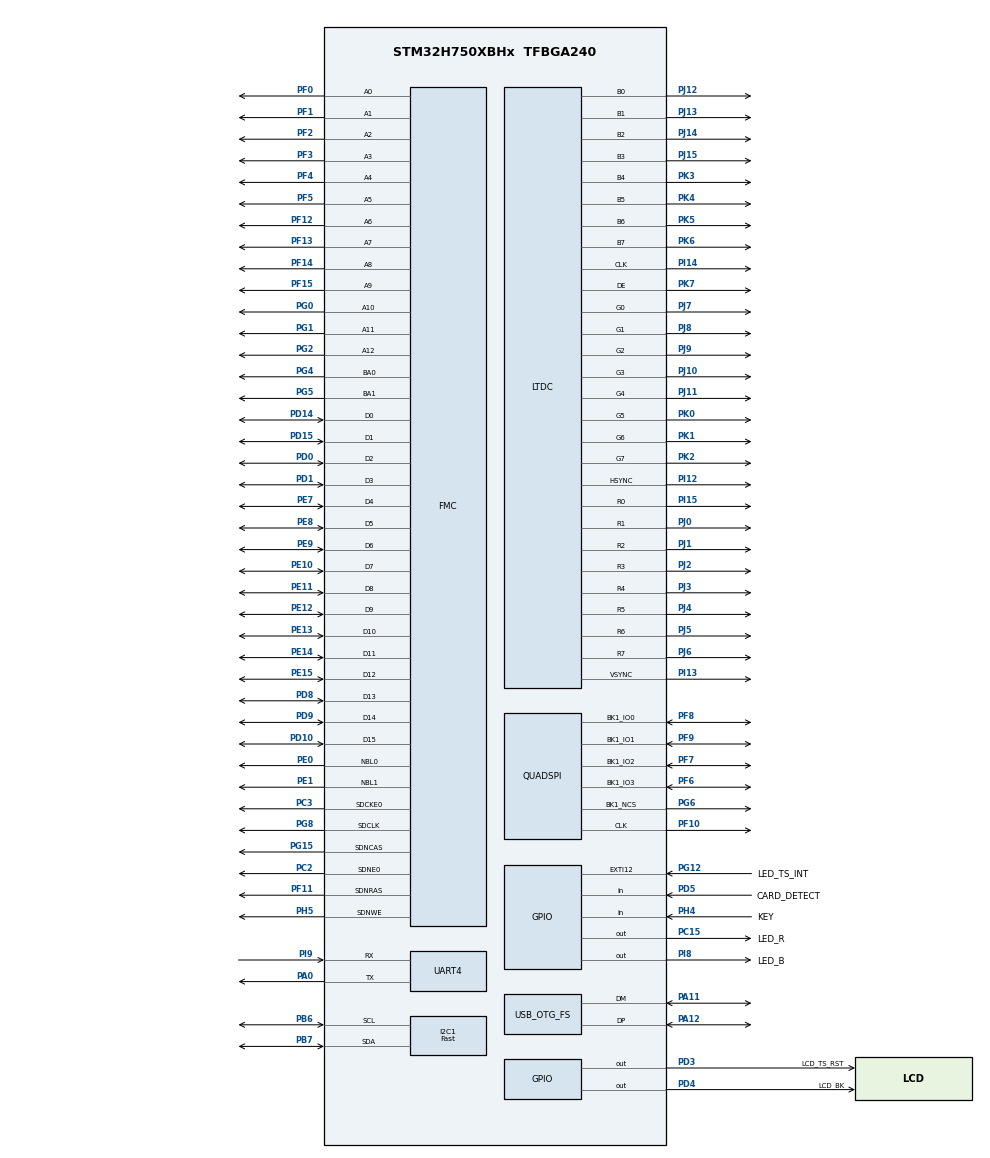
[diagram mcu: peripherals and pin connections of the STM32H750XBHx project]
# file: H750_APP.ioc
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CORTEX_M7.AccessPermission_S-Cortex_Memory_Protection_Unit_Region1_Settings_S=MPU_REGION_PRIV_RO
CORTEX_M7.AccessPermission_S-Cortex_Memory_Protection_Unit_Region2_Settings_S=MPU_REGION_FULL_ACCESS
CORTEX_M7.AccessPermission_S-Cortex_Memory_Protection_Unit_Region3_Settings_S=MPU_REGION_PRIV_RO
CORTEX_M7.AccessPermission_S-Cortex_Memory_Protection_Unit_Region4_Settings_S=MPU_REGION_FULL_ACCESS
CORTEX_M7.BaseAddress_S-Cortex_Memory_Protection_Unit_Region1_Settings_S=0x08000000
CORTEX_M7.BaseAddress_S-Cortex_Memory_Protection_Unit_Region2_Settings_S=0x24040000
CORTEX_M7.BaseAddress_S-Cortex_Memory_Protection_Unit_Region3_Settings_S=0x90000000
CORTEX_M7.BaseAddress_S-Cortex_Memory_Protection_Unit_Region4_Settings_S=0xC0000000
CORTEX_M7.CPU_DCache=Enabled
CORTEX_M7.CPU_ICache=Enabled
CORTEX_M7.DisableExec_S-Cortex_Memory_Protection_Unit_Region4_Settings_S=MPU_INSTRUCTION_ACCESS_DISABLE
CORTEX_M7.Enable_S-Cortex_Memory_Protection_Unit_Region1_Settings_S=MPU_REGION_ENABLE
CORTEX_M7.Enable_S-Cortex_Memory_Protection_Unit_Region2_Settings_S=MPU_REGION_ENABLE
CORTEX_M7.Enable_S-Cortex_Memory_Protection_Unit_Region3_Settings_S=MPU_REGION_ENABLE
CORTEX_M7.Enable_S-Cortex_Memory_Protection_Unit_Region4_Settings_S=MPU_REGION_ENABLE
CORTEX_M7.Enable_S-Cortex_Memory_Protection_Unit_Region5_Settings_S=__NULL
CORTEX_M7.IsBufferable_S-Cortex_Memory_Protection_Unit_Region4_Settings_S=MPU_ACCESS_BUFFERABLE
CORTEX_M7.IsCacheable_S-Cortex_Memory_Protection_Unit_Region1_Settings_S=MPU_ACCESS_CACHEABLE
CORTEX_M7.IsCacheable_S-Cortex_Memory_Protection_Unit_Region3_Settings_S=MPU_ACCESS_CACHEABLE
CORTEX_M7.IsCacheable_S-Cortex_Memory_Protection_Unit_Region4_Settings_S=MPU_ACCESS_CACHEABLE
CORTEX_M7.IsShareable_S-Cortex_Memory_Protection_Unit_Region2_Settings_S=MPU_ACCESS_SHAREABLE
CORTEX_M7.Number_S-Cortex_Memory_Protection_Unit_Region2_Settings_S=MPU_REGION_NUMBER2
CORTEX_M7.Number_S-Cortex_Memory_Protection_Unit_Region3_Settings_S=MPU_REGION_NUMBER3
CORTEX_M7.Number_S-Cortex_Memory_Protection_Unit_Region4_Settings_S=MPU_REGION_NUMBER4
CORTEX_M7.Size_S-Cortex_Memory_Protection_Unit_Region1_Settings_S=MPU_REGION_SIZE_128KB
CORTEX_M7.Size_S-Cortex_Memory_Protection_Unit_Region2_Settings_S=MPU_REGION_SIZE_512KB
CORTEX_M7.Size_S-Cortex_Memory_Protection_Unit_Region3_Settings_S=MPU_REGION_SIZE_16MB
CORTEX_M7.Size_S-Cortex_Memory_Protection_Unit_Region4_Settings_S=MPU_REGION_SIZE_32MB
CORTEX_M7.SubRegionDisable_S-Cortex_Memory_Protection_Unit_Region2_Settings_S=0xE0
CORTEX_M7.TypeExtField_S-Cortex_Memory_Protection_Unit_Region2_Settings_S=MPU_TEX_LEVEL1
CORTEX_M7.TypeExtField_S-Cortex_Memory_Protection_Unit_Region4_Settings_S=MPU_TEX_LEVEL1
CORTEX_M7.default_mode_Activation=1
Dma.I2C1_RX.0.Direction=DMA_PERIPH_TO_MEMORY
Dma.I2C1_RX.0.EventEnable=DISABLE
Dma.I2C1_RX.0.FIFOMode=DMA_FIFOMODE_DISABLE
Dma.I2C1_RX.0.Instance=DMA1_Stream0
Dma.I2C1_RX.0.MemDataAlignment=DMA_MDATAALIGN_BYTE
Dma.I2C1_RX.0.MemInc=DMA_MINC_ENABLE
Dma.I2C1_RX.0.Mode=DMA_NORMAL
Dma.I2C1_RX.0.PeriphDataAlignment=DMA_PDATAALIGN_BYTE
Dma.I2C1_RX.0.PeriphInc=DMA_PINC_DISABLE
Dma.I2C1_RX.0.Polarity=HAL_DMAMUX_REQ_GEN_RISING
Dma.I2C1_RX.0.Priority=DMA_PRIORITY_LOW
Dma.I2C1_RX.0.RequestNumber=1
Dma.I2C1_RX.0.SignalID=NONE
Dma.I2C1_RX.0.SyncEnable=DISABLE
Dma.I2C1_RX.0.SyncPolarity=HAL_DMAMUX_SYNC_NO_EVENT
Dma.I2C1_RX.0.SyncRequestNumber=1
Dma.I2C1_RX.0.SyncSignalID=NONE
Dma.I2C1_TX.1.Direction=DMA_MEMORY_TO_PERIPH
Dma.I2C1_TX.1.EventEnable=DISABLE
Dma.I2C1_TX.1.FIFOMode=DMA_FIFOMODE_DISABLE
Dma.I2C1_TX.1.Instance=DMA1_Stream1
Dma.I2C1_TX.1.MemDataAlignment=DMA_MDATAALIGN_BYTE
Dma.I2C1_TX.1.MemInc=DMA_MINC_ENABLE
Dma.I2C1_TX.1.Mode=DMA_NORMAL
Dma.I2C1_TX.1.PeriphDataAlignment=DMA_PDATAALIGN_BYTE
Dma.I2C1_TX.1.PeriphInc=DMA_PINC_DISABLE
Dma.I2C1_TX.1.Polarity=HAL_DMAMUX_REQ_GEN_RISING
Dma.I2C1_TX.1.Priority=DMA_PRIORITY_LOW
Dma.I2C1_TX.1.RequestNumber=1
Dma.I2C1_TX.1.SignalID=NONE
Dma.I2C1_TX.1.SyncEnable=DISABLE
Dma.I2C1_TX.1.SyncPolarity=HAL_DMAMUX_SYNC_NO_EVENT
Dma.I2C1_TX.1.SyncRequestNumber=1
Dma.I2C1_TX.1.SyncSignalID=NONE
Dma.Request0=I2C1_RX
Dma.Request1=I2C1_TX
FMC.CASLatency1=FMC_SDRAM_CAS_LATENCY_2
FMC.ColumnBitsNumber1=FMC_SDRAM_COLUMN_BITS_NUM_9
FMC.ExitSelfRefreshDelay1=8
FMC.LoadToActiveDelay1=2
FMC.RCDDelay1=2
FMC.RPDelay1=2
FMC.ReadBurst1=FMC_SDRAM_RBURST_ENABLE
FMC.RowCycleDelay1=6
FMC.SDClockPeriod1=FMC_SDRAM_CLOCK_PERIOD_2
FMC.SelfRefreshTime1=6
FMC.WriteRecoveryTime1=4
FREERTOS.Tasks01=defaultTask,24,256,StartDefaultTask,Default,NULL,Dynamic,NULL,NULL
FREERTOS.configENABLE_FPU=1
FREERTOS.configRECORD_STACK_HIGH_ADDRESS=1
FREERTOS.configTOTAL_HEAP_SIZE=65536
FREERTOS.configUSE_NEWLIB_REENTRANT=1
I2C1.CustomTiming=Disabled
I2C1.I2C_Fall_Time=0
I2C1.I2C_Rise_Time=0
I2C1.I2C_Speed_Mode=I2C_Fast
I2C1.Timing=0x00B03FDB
LTDC.ActiveH=272
LTDC.ActiveW=480
LTDC.Blue=255
LTDC.Green=0
LTDC.Green_L0=255
LTDC.HBP=40
LTDC.HFP=5
LTDC.HSync=1
LTDC.ImageHeight_L0=272
LTDC.ImageWidth_L0=480
LTDC.Layers=0
LTDC.Red=0
LTDC.VBP=8
LTDC.VFP=8
LTDC.VSync=1
LTDC.WindowX1_L0=480
LTDC.WindowY1_L0=272
Mcu.Family=STM32H7
Mcu.Name=STM32H750XBHx
Mcu.Package=TFBGA240
NVIC.DMA1_Stream0_IRQn=true\:5\:0\:false\:false\:true\:true\:false\:true\:true
NVIC.DMA1_Stream1_IRQn=true\:5\:0\:false\:false\:true\:true\:false\:true\:true
NVIC.EXTI15_10_IRQn=true\:5\:0\:false\:false\:true\:true\:true\:true\:true
NVIC.I2C1_ER_IRQn=true\:5\:0\:false\:false\:true\:true\:true\:true\:true
NVIC.I2C1_EV_IRQn=true\:5\:0\:false\:false\:true\:true\:true\:true\:true
NVIC.LTDC_IRQn=true\:5\:0\:false\:false\:true\:true\:true\:true\:true
NVIC.OTG_FS_EP1_IN_IRQn=true\:5\:0\:false\:false\:true\:true\:true\:true\:true
NVIC.OTG_FS_EP1_OUT_IRQn=true\:5\:0\:false\:false\:true\:true\:true\:true\:true
NVIC.OTG_FS_IRQn=true\:5\:0\:false\:false\:true\:true\:false\:true\:true
NVIC.PriorityGroup=NVIC_PRIORITYGROUP_4
PA0.Mode=Asynchronous
PA0.Signal=UART4_TX
PA11.Mode=Device_Only
PA11.Signal=USB_OTG_FS_DM
PA12.Mode=Device_Only
PA12.Signal=USB_OTG_FS_DP
PA13\ (JTMS/SWDIO).Mode=Serial_Wire
PA13\ (JTMS/SWDIO).Signal=DEBUG_JTMS-SWDIO
PA14\ (JTCK/SWCLK).Mode=Serial_Wire
PA14\ (JTCK/SWCLK).Signal=DEBUG_JTCK-SWCLK
PB6.GPIO_Pu=GPIO_PULLUP
PB6.Mode=I2C
PB6.Signal=I2C1_SCL
PB7.GPIO_Pu=GPIO_PULLUP
PB7.Mode=I2C
PB7.Signal=I2C1_SDA
PC14-OSC32_IN\ (OSC32_IN).Mode=LSE-External-Clock-Source
PC14-OSC32_IN\ (OSC32_IN).Signal=RCC_OSC32_IN
PC15-OSC32_OUT\ (OSC32_OUT).GPIO_Label=LED_R
PC15-OSC32_OUT\ (OSC32_OUT).PinState=GPIO_PIN_SET
PC15-OSC32_OUT\ (OSC32_OUT).Signal=GPIO_Output
PC2.Mode=SdramChipSelect1_1
PC2.Signal=FMC_SDNE0
PC3.Mode=SdramChipSelect1_1
PC3.Signal=FMC_SDCKE0
PD0.Signal=FMC_D2_DA2
PD1.Signal=FMC_D3_DA3
PD10.Signal=FMC_D15_DA15
PD14.Signal=FMC_D0_DA0
PD15.Signal=FMC_D1_DA1
PD3.GPIO_Label=LCD_TS_RST
PD3.Signal=GPIO_Output
PD4.GPIO_Label=LCD_BK
PD4.Signal=GPIO_Output
PD5.GPIO_Label=CARD_DETECT
PD5.Signal=GPIO_Input
PD8.Signal=FMC_D13_DA13
PD9.Signal=FMC_D14_DA14
PE0.Signal=FMC_NBL0
PE1.Signal=FMC_NBL1
PE10.Signal=FMC_D7_DA7
PE11.Signal=FMC_D8_DA8
PE12.Signal=FMC_D9_DA9
PE13.Signal=FMC_D10_DA10
PE14.Signal=FMC_D11_DA11
PE15.Signal=FMC_D12_DA12
PE7.Signal=FMC_D4_DA4
PE8.Signal=FMC_D5_DA5
PE9.Signal=FMC_D6_DA6
PF0.Signal=FMC_A0
PF1.Signal=FMC_A1
PF10.Mode=Single Bank 1
PF10.Signal=QUADSPI_CLK
PF11.Signal=FMC_SDNRAS
PF12.Signal=FMC_A6
PF13.Signal=FMC_A7
PF14.Signal=FMC_A8
PF15.Signal=FMC_A9
PF2.Signal=FMC_A2
PF3.Signal=FMC_A3
PF4.Signal=FMC_A4
PF5.Signal=FMC_A5
PF6.Mode=Single Bank 1
PF6.Signal=QUADSPI_BK1_IO3
PF7.Mode=Single Bank 1
PF7.Signal=QUADSPI_BK1_IO2
PF8.Mode=Single Bank 1
PF8.Signal=QUADSPI_BK1_IO0
PF9.Mode=Single Bank 1
PF9.Signal=QUADSPI_BK1_IO1
PG0.Signal=FMC_A10
PG1.Signal=FMC_A11
PG12.GPIO_Label=LED_TS_INT
PG12.GPIO_PuPd=GPIO_PULLDOWN
PG12.Signal=GPXTI12
PG15.Signal=FMC_SDNCAS
PG2.Signal=FMC_A12
PG4.Signal=FMC_A14_BA0
PG5.Signal=FMC_A15_BA1
PG6.Mode=Single Bank 1
PG6.Signal=QUADSPI_BK1_NCS
PG8.Signal=FMC_SDCLK
PH0-OSC_IN\ (PH0).Mode=HSE-External-Oscillator
PH0-OSC_IN\ (PH0).Signal=RCC_OSC_IN
PH1-OSC_OUT\ (PH1).Mode=HSE-External-Oscillator
PH1-OSC_OUT\ (PH1).Signal=RCC_OSC_OUT
PH4.GPIO_Label=KEY
PH4.Signal=GPIO_Input
PH5.Signal=FMC_SDNWE
PI12.GPIO_Speed=GPIO_SPEED_FREQ_HIGH
PI12.Mode=RGB888
PI12.Signal=LTDC_HSYNC
PI13.GPIO_Speed=GPIO_SPEED_FREQ_HIGH
PI13.Mode=RGB888
PI13.Signal=LTDC_VSYNC
PI14.GPIO_Speed=GPIO_SPEED_FREQ_HIGH
PI14.Mode=RGB888
PI14.Signal=LTDC_CLK
PI15.GPIO_Speed=GPIO_SPEED_FREQ_HIGH
PI15.Mode=RGB888
PI15.Signal=LTDC_R0
PI8.GPIO_Label=LED_B
PI8.PinState=GPIO_PIN_SET
PI8.Signal=GPIO_Output
PI9.Mode=Asynchronous
PI9.Signal=UART4_RX
PJ0.GPIO_Speed=GPIO_SPEED_FREQ_HIGH
PJ0.Mode=RGB888
PJ0.Signal=LTDC_R1
PJ1.GPIO_Speed=GPIO_SPEED_FREQ_HIGH
PJ1.Mode=RGB888
PJ1.Signal=LTDC_R2
PJ10.GPIO_Speed=GPIO_SPEED_FREQ_HIGH
PJ10.Mode=RGB888
PJ10.Signal=LTDC_G3
PJ11.GPIO_Speed=GPIO_SPEED_FREQ_HIGH
PJ11.Mode=RGB888
PJ11.Signal=LTDC_G4
PJ12.GPIO_Speed=GPIO_SPEED_FREQ_HIGH
PJ12.Mode=RGB888
PJ12.Signal=LTDC_B0
PJ13.GPIO_Speed=GPIO_SPEED_FREQ_HIGH
PJ13.Mode=RGB888
PJ13.Signal=LTDC_B1
PJ14.GPIO_Speed=GPIO_SPEED_FREQ_HIGH
PJ14.Mode=RGB888
PJ14.Signal=LTDC_B2
PJ15.GPIO_Speed=GPIO_SPEED_FREQ_HIGH
PJ15.Mode=RGB888
PJ15.Signal=LTDC_B3
PJ2.GPIO_Speed=GPIO_SPEED_FREQ_HIGH
PJ2.Mode=RGB888
PJ2.Signal=LTDC_R3
PJ3.GPIO_Speed=GPIO_SPEED_FREQ_HIGH
PJ3.Mode=RGB888
PJ3.Signal=LTDC_R4
PJ4.GPIO_Speed=GPIO_SPEED_FREQ_HIGH
PJ4.Mode=RGB888
PJ4.Signal=LTDC_R5
PJ5.GPIO_Speed=GPIO_SPEED_FREQ_HIGH
PJ5.Mode=RGB888
PJ5.Signal=LTDC_R6
PJ6.GPIO_Speed=GPIO_SPEED_FREQ_HIGH
PJ6.Mode=RGB888
PJ6.Signal=LTDC_R7
PJ7.GPIO_Speed=GPIO_SPEED_FREQ_HIGH
PJ7.Mode=RGB888
PJ7.Signal=LTDC_G0
PJ8.GPIO_Speed=GPIO_SPEED_FREQ_HIGH
PJ8.Mode=RGB888
PJ8.Signal=LTDC_G1
PJ9.GPIO_Speed=GPIO_SPEED_FREQ_HIGH
PJ9.Mode=RGB888
PJ9.Signal=LTDC_G2
PK0.GPIO_Speed=GPIO_SPEED_FREQ_HIGH
PK0.Mode=RGB888
PK0.Signal=LTDC_G5
PK1.GPIO_Speed=GPIO_SPEED_FREQ_HIGH
PK1.Mode=RGB888
PK1.Signal=LTDC_G6
PK2.GPIO_Speed=GPIO_SPEED_FREQ_HIGH
PK2.Mode=RGB888
PK2.Signal=LTDC_G7
PK3.GPIO_Speed=GPIO_SPEED_FREQ_HIGH
PK3.Mode=RGB888
PK3.Signal=LTDC_B4
PK4.GPIO_Speed=GPIO_SPEED_FREQ_HIGH
PK4.Mode=RGB888
PK4.Signal=LTDC_B5
PK5.GPIO_Speed=GPIO_SPEED_FREQ_HIGH
PK5.Mode=RGB888
PK5.Signal=LTDC_B6
PK6.GPIO_Speed=GPIO_SPEED_FREQ_HIGH
PK6.Mode=RGB888
PK6.Signal=LTDC_B7
PK7.GPIO_Speed=GPIO_SPEED_FREQ_HIGH
PK7.Mode=RGB888
PK7.Signal=LTDC_DE
ProjectManager.HeapSize=0x400
ProjectManager.StackSize=0x800
ProjectManager.TargetToolchain=CMake
QUADSPI.ClockPrescaler=1
QUADSPI.FlashSize=24
RCC.ADCCLockSelection=RCC_ADCCLKSOURCE_CLKP
RCC.ADCFreq_Value=64000000
RCC.APB1Freq_Value=120000000
RCC.APB2Freq_Value=120000000
RCC.APB3Freq_Value=120000000
RCC.APB4Freq_Value=120000000
RCC.CortexFreq_Value=480000000
RCC.D1PPRE=RCC_APB3_DIV2
RCC.D2PPRE1=RCC_APB1_DIV2
RCC.D2PPRE2=RCC_APB2_DIV2
RCC.D3PPRE=RCC_APB4_DIV2
RCC.DIVM1=5
RCC.DIVM2=2
RCC.DIVM3=1
RCC.DIVN1=192
RCC.DIVN2=48
RCC.DIVN3=6
RCC.DIVQ2=3
RCC.DIVQ3=1
RCC.DIVR2=3
RCC.DIVR3=15
RCC.FMCCLockSelection=RCC_FMCCLKSOURCE_PLL2
RCC.HCLKFreq_Value=240000000
RCC.HPRE=RCC_HCLK_DIV2
RCC.PLL2FRACN=0
RCC.PLL3FRACN=0
RCC.PLLFRACN=0
RCC.PLLSourceVirtual=RCC_PLLSOURCE_HSE
RCC.QSPICLockSelection=RCC_QSPICLKSOURCE_PLL2
RCC.SDMMC1CLockSelection=RCC_SDMMCCLKSOURCE_PLL2
RCC.SYSCLKFreq_VALUE=480000000
RCC.SYSCLKSource=RCC_SYSCLKSOURCE_PLLCLK
RCC.USBCLockSelection=RCC_USBCLKSOURCE_HSI48
RCC.USBFreq_Value=48000000
SH.FMC_A0.0=FMC_A0,13b-sda1
SH.FMC_A1.0=FMC_A1,13b-sda1
SH.FMC_A10.0=FMC_A10,13b-sda1
SH.FMC_A11.0=FMC_A11,13b-sda1
SH.FMC_A12.0=FMC_A12,13b-sda1
SH.FMC_A14_BA0.0=FMC_BA0,FourSdramBanks1
SH.FMC_A15_BA1.0=FMC_BA1,FourSdramBanks1
SH.FMC_A2.0=FMC_A2,13b-sda1
SH.FMC_A3.0=FMC_A3,13b-sda1
SH.FMC_A4.0=FMC_A4,13b-sda1
SH.FMC_A5.0=FMC_A5,13b-sda1
SH.FMC_A6.0=FMC_A6,13b-sda1
SH.FMC_A7.0=FMC_A7,13b-sda1
SH.FMC_A8.0=FMC_A8,13b-sda1
SH.FMC_A9.0=FMC_A9,13b-sda1
SH.FMC_D0_DA0.0=FMC_D0,sd-16b-d1
SH.FMC_D10_DA10.0=FMC_D10,sd-16b-d1
SH.FMC_D11_DA11.0=FMC_D11,sd-16b-d1
SH.FMC_D12_DA12.0=FMC_D12,sd-16b-d1
SH.FMC_D13_DA13.0=FMC_D13,sd-16b-d1
SH.FMC_D14_DA14.0=FMC_D14,sd-16b-d1
SH.FMC_D15_DA15.0=FMC_D15,sd-16b-d1
SH.FMC_D1_DA1.0=FMC_D1,sd-16b-d1
SH.FMC_D2_DA2.0=FMC_D2,sd-16b-d1
SH.FMC_D3_DA3.0=FMC_D3,sd-16b-d1
SH.FMC_D4_DA4.0=FMC_D4,sd-16b-d1
SH.FMC_D5_DA5.0=FMC_D5,sd-16b-d1
SH.FMC_D6_DA6.0=FMC_D6,sd-16b-d1
SH.FMC_D7_DA7.0=FMC_D7,sd-16b-d1
SH.FMC_D8_DA8.0=FMC_D8,sd-16b-d1
SH.FMC_D9_DA9.0=FMC_D9,sd-16b-d1
SH.FMC_NBL0.0=FMC_NBL0,Sd2ByteEnable1
SH.FMC_NBL1.0=FMC_NBL1,Sd2ByteEnable1
SH.FMC_SDCLK.0=FMC_SDCLK,13b-sda1
SH.FMC_SDNCAS.0=FMC_SDNCAS,13b-sda1
SH.FMC_SDNRAS.0=FMC_SDNRAS,13b-sda1
SH.FMC_SDNWE.0=FMC_SDNWE,13b-sda1
USB_DEVICE.CLASS_NAME_FS=HID
USB_DEVICE.USBD_MAX_NUM_CONFIGURATION-HID_FS=1
USB_DEVICE.USBD_SELF_POWERED-HID_FS=0
USB_DEVICE.VirtualMode-HID_FS=Hid
USB_DEVICE.VirtualModeFS=Hid_FS
USB_OTG_FS.VirtualMode=Device_Only
VP_FREERTOS_VS_CMSIS_V2.Mode=CMSIS_V2
VP_MEMORYMAP_VS_MEMORYMAP.Mode=CurAppReg
VP_USB_DEVICE_VS_USB_DEVICE_HID_FS.Mode=HID_FS
board=custom

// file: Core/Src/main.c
/* USER CODE BEGIN Header */
/**
 ******************************************************************************
 * @file           : main.c
 * @brief          : Main program body
 ******************************************************************************
 * @attention
 *
 * Copyright (c) 2025 STMicroelectronics.
 * All rights reserved.
 *
 * This software is licensed under terms that can be found in the LICENSE file
 * in the root directory of this software component.
 * If no LICENSE file comes with this software, it is provided AS-IS.
 *
 ******************************************************************************
 */
/* USER CODE END Header */
#include "main.h"
#include "cmsis_os.h"
#include "dma.h"
#include "i2c.h"
#include "ltdc.h"
#include "memorymap.h"
#include "usart.h"
#include "usb_device.h"
#include "gpio.h"

/* USER CODE BEGIN Includes */
#include "SEGGER_RTT.h"
#include "usbd_hid.h"

/* USER CODE END Includes */

void SystemClock_Config(void);
void PeriphCommonClock_Config(void);
static void MPU_Config(void);
void MX_FREERTOS_Init(void);

int main(void)
{

  /* MPU Configuration--------------------------------------------------------*/
  MPU_Config();

  /* Enable the CPU Cache */

  /* Enable I-Cache---------------------------------------------------------*/
  SCB_EnableICache();

  /* Enable D-Cache---------------------------------------------------------*/
  SCB_EnableDCache();

  /* MCU Configuration--------------------------------------------------------*/

  /* Reset of all peripherals, Initializes the Flash interface and the Systick. */
  HAL_Init();

  /* USER CODE BEGIN Init */
#if 0
  /* USER CODE END Init */

  /* Configure the system clock */
  SystemClock_Config();

  /* Configure the peripherals common clocks */
  PeriphCommonClock_Config();

  /* USER CODE BEGIN SysInit */
#endif
  /* USER CODE END SysInit */

  /* Initialize all configured peripherals */
  MX_GPIO_Init();
  MX_DMA_Init();
  MX_LTDC_Init();
  MX_I2C1_Init();
  MX_UART4_Init();
  /* USER CODE BEGIN 2 */
  SEGGER_RTT_Init();
  /* USER CODE END 2 */

  /* Init scheduler */
  osKernelInitialize();

  /* Call init function for freertos objects (in cmsis_os2.c) */
  MX_FREERTOS_Init();

  /* Start scheduler */
  osKernelStart();

  /* We should never get here as control is now taken by the scheduler */

  /* Infinite loop */
    while (1)
    {

    }
}

void SystemClock_Config(void)
{
  RCC_OscInitTypeDef RCC_OscInitStruct = {0};
  RCC_ClkInitTypeDef RCC_ClkInitStruct = {0};

  /** Supply configuration update enable
  */
  HAL_PWREx_ConfigSupply(PWR_LDO_SUPPLY);

  /** Configure the main internal regulator output voltage
  */
  __HAL_PWR_VOLTAGESCALING_CONFIG(PWR_REGULATOR_VOLTAGE_SCALE1);

  while(!__HAL_PWR_GET_FLAG(PWR_FLAG_VOSRDY)) {}

  __HAL_RCC_SYSCFG_CLK_ENABLE();
  __HAL_PWR_VOLTAGESCALING_CONFIG(PWR_REGULATOR_VOLTAGE_SCALE0);

  while(!__HAL_PWR_GET_FLAG(PWR_FLAG_VOSRDY)) {}

  /** Initializes the RCC Oscillators according to the specified parameters
  * in the RCC_OscInitTypeDef structure.
  */
  RCC_OscInitStruct.OscillatorType = RCC_OSCILLATORTYPE_HSI48|RCC_OSCILLATORTYPE_HSE;
  RCC_OscInitStruct.HSEState = RCC_HSE_ON;
  RCC_OscInitStruct.HSI48State = RCC_HSI48_ON;
  RCC_OscInitStruct.PLL.PLLState = RCC_PLL_ON;
  RCC_OscInitStruct.PLL.PLLSource = RCC_PLLSOURCE_HSE;
  RCC_OscInitStruct.PLL.PLLM = 5;
  RCC_OscInitStruct.PLL.PLLN = 192;
  RCC_OscInitStruct.PLL.PLLP = 2;
  RCC_OscInitStruct.PLL.PLLQ = 2;
  RCC_OscInitStruct.PLL.PLLR = 2;
  RCC_OscInitStruct.PLL.PLLRGE = RCC_PLL1VCIRANGE_2;
  RCC_OscInitStruct.PLL.PLLVCOSEL = RCC_PLL1VCOWIDE;
  RCC_OscInitStruct.PLL.PLLFRACN = 0;
  if (HAL_RCC_OscConfig(&RCC_OscInitStruct) != HAL_OK)
  {
    Error_Handler();
  }

  /** Initializes the CPU, AHB and APB buses clocks
  */
  RCC_ClkInitStruct.ClockType = RCC_CLOCKTYPE_HCLK|RCC_CLOCKTYPE_SYSCLK
                              |RCC_CLOCKTYPE_PCLK1|RCC_CLOCKTYPE_PCLK2
                              |RCC_CLOCKTYPE_D3PCLK1|RCC_CLOCKTYPE_D1PCLK1;
  RCC_ClkInitStruct.SYSCLKSource = RCC_SYSCLKSOURCE_PLLCLK;
  RCC_ClkInitStruct.SYSCLKDivider = RCC_SYSCLK_DIV1;
  RCC_ClkInitStruct.AHBCLKDivider = RCC_HCLK_DIV2;
  RCC_ClkInitStruct.APB3CLKDivider = RCC_APB3_DIV2;
  RCC_ClkInitStruct.APB1CLKDivider = RCC_APB1_DIV2;
  RCC_ClkInitStruct.APB2CLKDivider = RCC_APB2_DIV2;
  RCC_ClkInitStruct.APB4CLKDivider = RCC_APB4_DIV2;

  if (HAL_RCC_ClockConfig(&RCC_ClkInitStruct, FLASH_LATENCY_4) != HAL_OK)
  {
    Error_Handler();
  }
}

void PeriphCommonClock_Config(void)
{
  RCC_PeriphCLKInitTypeDef PeriphClkInitStruct = {0};

  /** Initializes the peripherals clock
  */
  PeriphClkInitStruct.PeriphClockSelection = RCC_PERIPHCLK_FMC|RCC_PERIPHCLK_QSPI;
  PeriphClkInitStruct.PLL2.PLL2M = 2;
  PeriphClkInitStruct.PLL2.PLL2N = 48;
  PeriphClkInitStruct.PLL2.PLL2P = 2;
  PeriphClkInitStruct.PLL2.PLL2Q = 3;
  PeriphClkInitStruct.PLL2.PLL2R = 3;
  PeriphClkInitStruct.PLL2.PLL2RGE = RCC_PLL2VCIRANGE_3;
  PeriphClkInitStruct.PLL2.PLL2VCOSEL = RCC_PLL2VCOWIDE;
  PeriphClkInitStruct.PLL2.PLL2FRACN = 0;
  PeriphClkInitStruct.FmcClockSelection = RCC_FMCCLKSOURCE_PLL2;
  PeriphClkInitStruct.QspiClockSelection = RCC_QSPICLKSOURCE_PLL2;
  if (HAL_RCCEx_PeriphCLKConfig(&PeriphClkInitStruct) != HAL_OK)
  {
    Error_Handler();
  }
}

 /* MPU Configuration */

void MPU_Config(void)
{
  MPU_Region_InitTypeDef MPU_InitStruct = {0};

  /* Disables the MPU */
  HAL_MPU_Disable();

  /** Initializes and configures the Region and the memory to be protected
  */
  MPU_InitStruct.Enable = MPU_REGION_ENABLE;
  MPU_InitStruct.Number = MPU_REGION_NUMBER0;
  MPU_InitStruct.BaseAddress = 0x0;
  MPU_InitStruct.Size = MPU_REGION_SIZE_4GB;
  MPU_InitStruct.SubRegionDisable = 0x87;
  MPU_InitStruct.TypeExtField = MPU_TEX_LEVEL0;
  MPU_InitStruct.AccessPermission = MPU_REGION_NO_ACCESS;
  MPU_InitStruct.DisableExec = MPU_INSTRUCTION_ACCESS_DISABLE;
  MPU_InitStruct.IsShareable = MPU_ACCESS_SHAREABLE;
  MPU_InitStruct.IsCacheable = MPU_ACCESS_NOT_CACHEABLE;
  MPU_InitStruct.IsBufferable = MPU_ACCESS_NOT_BUFFERABLE;

  HAL_MPU_ConfigRegion(&MPU_InitStruct);

  /** Initializes and configures the Region and the memory to be protected
  */
  MPU_InitStruct.Number = MPU_REGION_NUMBER1;
  MPU_InitStruct.BaseAddress = 0x08000000;
  MPU_InitStruct.Size = MPU_REGION_SIZE_128KB;
  MPU_InitStruct.SubRegionDisable = 0x0;
  MPU_InitStruct.AccessPermission = MPU_REGION_PRIV_RO;
  MPU_InitStruct.DisableExec = MPU_INSTRUCTION_ACCESS_ENABLE;
  MPU_InitStruct.IsShareable = MPU_ACCESS_NOT_SHAREABLE;
  MPU_InitStruct.IsCacheable = MPU_ACCESS_CACHEABLE;

  HAL_MPU_ConfigRegion(&MPU_InitStruct);

  /** Initializes and configures the Region and the memory to be protected
  */
  MPU_InitStruct.Number = MPU_REGION_NUMBER2;
  MPU_InitStruct.BaseAddress = 0x24040000;
  MPU_InitStruct.Size = MPU_REGION_SIZE_512KB;
  MPU_InitStruct.SubRegionDisable = 0xE0;
  MPU_InitStruct.TypeExtField = MPU_TEX_LEVEL1;
  MPU_InitStruct.AccessPermission = MPU_REGION_FULL_ACCESS;
  MPU_InitStruct.IsShareable = MPU_ACCESS_SHAREABLE;
  MPU_InitStruct.IsCacheable = MPU_ACCESS_NOT_CACHEABLE;

  HAL_MPU_ConfigRegion(&MPU_InitStruct);

  /** Initializes and configures the Region and the memory to be protected
  */
  MPU_InitStruct.Number = MPU_REGION_NUMBER3;
  MPU_InitStruct.BaseAddress = 0x90000000;
  MPU_InitStruct.Size = MPU_REGION_SIZE_16MB;
  MPU_InitStruct.SubRegionDisable = 0x0;
  MPU_InitStruct.TypeExtField = MPU_TEX_LEVEL0;
  MPU_InitStruct.AccessPermission = MPU_REGION_PRIV_RO;
  MPU_InitStruct.IsShareable = MPU_ACCESS_NOT_SHAREABLE;
  MPU_InitStruct.IsCacheable = MPU_ACCESS_CACHEABLE;

  HAL_MPU_ConfigRegion(&MPU_InitStruct);

  /** Initializes and configures the Region and the memory to be protected
  */
  MPU_InitStruct.Number = MPU_REGION_NUMBER4;
  MPU_InitStruct.BaseAddress = 0xC0000000;
  MPU_InitStruct.Size = MPU_REGION_SIZE_32MB;
  MPU_InitStruct.TypeExtField = MPU_TEX_LEVEL1;
  MPU_InitStruct.AccessPermission = MPU_REGION_FULL_ACCESS;
  MPU_InitStruct.DisableExec = MPU_INSTRUCTION_ACCESS_DISABLE;
  MPU_InitStruct.IsBufferable = MPU_ACCESS_BUFFERABLE;

  HAL_MPU_ConfigRegion(&MPU_InitStruct);
  /* Enables the MPU */
  HAL_MPU_Enable(MPU_PRIVILEGED_DEFAULT);

}

void Error_Handler(void)
{
    __disable_irq();
    while (1)
    {
    }
}

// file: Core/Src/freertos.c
/* USER CODE BEGIN Header */
/**
  ******************************************************************************
  * File Name          : freertos.c
  * Description        : Code for freertos applications
  ******************************************************************************
  * @attention
  *
  * Copyright (c) 2025 STMicroelectronics.
  * All rights reserved.
  *
  * This software is licensed under terms that can be found in the LICENSE file
  * in the root directory of this software component.
  * If no LICENSE file comes with this software, it is provided AS-IS.
  *
  ******************************************************************************
  */
/* USER CODE END Header */

#include "FreeRTOS.h"
#include "portmacro.h"
#include "projdefs.h"
#include "task.h"
#include "main.h"
#include "cmsis_os.h"

/* USER CODE BEGIN Includes */
#include "usbd_hid.h"
#include "usb_device.h"
#include "GT9147_driver.h"
#include "lvgl_driver.h"
#include "queue.h"

/* USER CODE END Includes */

/* Definitions for defaultTask */
osThreadId_t defaultTaskHandle;
const osThreadAttr_t defaultTask_attributes = {
  .name = "defaultTask",
  .stack_size = 256 * 4,
  .priority = (osPriority_t) osPriorityNormal,
};

void StartDefaultTask(void *argument);

extern void MX_USB_DEVICE_Init(void);
void MX_FREERTOS_Init(void); /* (MISRA C 2004 rule 8.1) */

void MX_FREERTOS_Init(void) {

  /* Create the thread(s) */
  /* creation of defaultTask */
  defaultTaskHandle = osThreadNew(StartDefaultTask, NULL, &defaultTask_attributes);

}

/* USER CODE BEGIN Header_StartDefaultTask */
typedef struct
{
    uint8_t L_ctrl : 1;
    uint8_t L_shift : 1;
    uint8_t L_Alt : 1;
    uint8_t L_gui : 1;
    uint8_t R_ctrl : 1;
    uint8_t R_shift : 1;
    uint8_t R_alt : 1;
    uint8_t R_gui : 1;
    uint8_t reserved;
    uint8_t keys[6];
} KeyboardData_t;

static QueueHandle_t usb_event_handel;

#define KEY_DELAY 20

/**
  * @brief  Function implementing the defaultTask thread.
  * @param  argument: Not used
  * @retval None
  */
/* USER CODE END Header_StartDefaultTask */
void StartDefaultTask(void *argument)
{
  /* init code for USB_DEVICE */
  MX_USB_DEVICE_Init();
  /* USER CODE BEGIN StartDefaultTask */
  UNUSED(argument);

  usb_event_handel = xQueueCreate(4, sizeof(const char *));
  gt9147_init();
  lvgl_init();
  /* Infinite loop */
  for(;;)
  {
      const char *keyseq = NULL;
      BaseType_t ret = xQueueReceive(usb_event_handel, &keyseq, 300);
      if (ret == pdPASS && keyseq != NULL)
      {
          KeyboardData_t Data_Buffer = {};
          Data_Buffer.L_ctrl = 1;
          USBD_HID_SendReport(&hUsbDeviceFS, (uint8_t *)&Data_Buffer, sizeof(Data_Buffer));
          vTaskDelay(KEY_DELAY);
          for (const char *key = keyseq; *key != 0; key++)
          {
              Data_Buffer.keys[0] = *key - 'A' + 4;
              USBD_HID_SendReport(&hUsbDeviceFS, (uint8_t *)&Data_Buffer, sizeof(Data_Buffer));
              vTaskDelay(KEY_DELAY);
              Data_Buffer.keys[0] = 0;
              USBD_HID_SendReport(&hUsbDeviceFS, (uint8_t *)&Data_Buffer, sizeof(Data_Buffer));
              vTaskDelay(KEY_DELAY);
          }
          vTaskDelay(KEY_DELAY);
          Data_Buffer.L_ctrl = 0;
          Data_Buffer.keys[0] = 0;
          USBD_HID_SendReport(&hUsbDeviceFS, (uint8_t *)&Data_Buffer, sizeof(Data_Buffer));
      }
      else
      {
          HAL_GPIO_TogglePin(LED_B_GPIO_Port, LED_B_Pin);
      }
  }
  /* USER CODE END StartDefaultTask */
}

/* USER CODE BEGIN Application */
int usb_push_keyseq(const char * const*seq, TickType_t xTicksToWait)
{
  return xQueueSend(usb_event_handel, seq, xTicksToWait);
}
/* USER CODE END Application */
